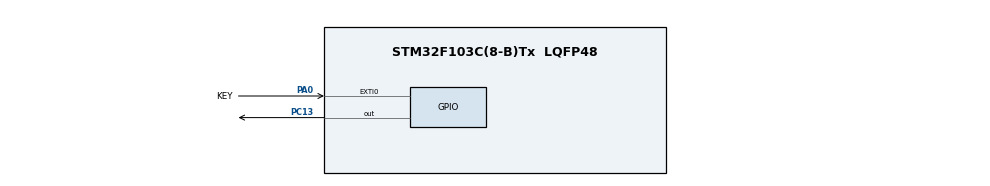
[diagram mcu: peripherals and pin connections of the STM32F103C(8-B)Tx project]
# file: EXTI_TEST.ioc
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Mcu.Family=STM32F1
Mcu.Name=STM32F103C(8-B)Tx
Mcu.Package=LQFP48
NVIC.EXTI0_IRQn=true\:0\:0\:false\:false\:true\:true\:true\:true
NVIC.PriorityGroup=NVIC_PRIORITYGROUP_4
PA0-WKUP.GPIO_Label=KEY
PA0-WKUP.GPIO_ModeDefaultEXTI=GPIO_MODE_IT_FALLING
PA0-WKUP.GPIO_PuPd=GPIO_PULLUP
PA0-WKUP.Signal=GPXTI0
PA13.Mode=Serial_Wire
PA13.Signal=SYS_JTMS-SWDIO
PA14.Mode=Serial_Wire
PA14.Signal=SYS_JTCK-SWCLK
PC13-TAMPER-RTC.GPIO_ModeDefaultOutputPP=GPIO_MODE_OUTPUT_OD
PC13-TAMPER-RTC.GPIO_PuPd=GPIO_NOPULL
PC13-TAMPER-RTC.PinState=GPIO_PIN_SET
PC13-TAMPER-RTC.Signal=GPIO_Output
ProjectManager.HeapSize=0x200
ProjectManager.StackSize=0x400
ProjectManager.TargetToolchain=MDK-ARM V5.32
RCC.APB1Freq_Value=8000000
RCC.APB2Freq_Value=8000000
board=custom

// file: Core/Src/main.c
/* USER CODE BEGIN Header */
/**
  ******************************************************************************
  * @file           : main.c
  * @brief          : Main program body
  ******************************************************************************
  * @attention
  *
  * Copyright (c) 2026 STMicroelectronics.
  * All rights reserved.
  *
  * This software is licensed under terms that can be found in the LICENSE file
  * in the root directory of this software component.
  * If no LICENSE file comes with this software, it is provided AS-IS.
  *
  ******************************************************************************
  */
/**
  * 工程：EXTI_Test —— 外部中断 + 软件消抖 + LED 翻转
  * 硬件：KEY 接 PA0（内部上拉，下降沿触发，按下接 GND）；LED 接 PC13（开漏输出，低电平点亮）
  * 时钟：只用内部 HSI 8 MHz，未启用 HSE，也没有开 PLL
  * 思路：EXTI 回调里只置标志、记时间戳，耗时的判断放到主循环，中断保持最短
  * 验证：每按一次按键，PC13 上的 LED 翻转一次
  */
/* USER CODE END Header */
#include "main.h"
#include "gpio.h"

void SystemClock_Config(void);

/* USER CODE BEGIN 0 */
volatile uint8_t key_flag=0;			// 中断置 1，通知主循环“有按键事件”；volatile 防止编译器把它缓存进寄存器
volatile uint32_t key_press_tick = 0;	// 记下按下时刻的 SysTick 毫秒数，主循环靠它算 20 ms 消抖窗口
/* USER CODE END 0 */

int main(void)
{

  /* MCU Configuration--------------------------------------------------------*/

  /* Reset of all peripherals, Initializes the Flash interface and the Systick. */
  HAL_Init();

  /* Configure the system clock */
  SystemClock_Config();

  /* Initialize all configured peripherals */
  MX_GPIO_Init();

  /* Infinite loop */
  /* USER CODE BEGIN WHILE */
  while (1)
  {
		/* 主循环：检测中断置下的标志，完成消抖确认后再翻转 LED */
		if(key_flag == 1)
		{
			/* 距按下已过 20 ms 才继续。机械抖动一般 <10 ms，等过再判定；
			   用“现在 - 当时”而不是“现在 > 当时+20”，是为了让 SysTick 回绕时依然算得对 */
			if((HAL_GetTick() - key_press_tick) >= 20)
			{
				key_flag = 0;		// 清标志：同一次按下只处理一次
				/* 再读一次引脚电平：仍为低说明是真按下，而不是抖动残留或已经松手 */
				if(HAL_GPIO_ReadPin(GPIOA, GPIO_PIN_0) == GPIO_PIN_RESET)
				{
					HAL_GPIO_TogglePin(GPIOC, GPIO_PIN_13);	// 翻转 LED：PC13 是开漏接上拉，低电平点亮
				}
			}

		}
    /* USER CODE END WHILE */

  }
}

void SystemClock_Config(void)
{
  RCC_OscInitTypeDef RCC_OscInitStruct = {0};
  RCC_ClkInitTypeDef RCC_ClkInitStruct = {0};

  /** Initializes the RCC Oscillators according to the specified parameters
  * in the RCC_OscInitTypeDef structure.
  */
  RCC_OscInitStruct.OscillatorType = RCC_OSCILLATORTYPE_HSI;
  RCC_OscInitStruct.HSIState = RCC_HSI_ON;
  RCC_OscInitStruct.HSICalibrationValue = RCC_HSICALIBRATION_DEFAULT;
  RCC_OscInitStruct.PLL.PLLState = RCC_PLL_NONE;
  if (HAL_RCC_OscConfig(&RCC_OscInitStruct) != HAL_OK)
  {
    Error_Handler();
  }

  /** Initializes the CPU, AHB and APB buses clocks
  */
  RCC_ClkInitStruct.ClockType = RCC_CLOCKTYPE_HCLK|RCC_CLOCKTYPE_SYSCLK
                              |RCC_CLOCKTYPE_PCLK1|RCC_CLOCKTYPE_PCLK2;
  RCC_ClkInitStruct.SYSCLKSource = RCC_SYSCLKSOURCE_HSI;
  RCC_ClkInitStruct.AHBCLKDivider = RCC_SYSCLK_DIV1;
  RCC_ClkInitStruct.APB1CLKDivider = RCC_HCLK_DIV1;
  RCC_ClkInitStruct.APB2CLKDivider = RCC_HCLK_DIV1;

  if (HAL_RCC_ClockConfig(&RCC_ClkInitStruct, FLASH_LATENCY_0) != HAL_OK)
  {
    Error_Handler();
  }
}

/* USER CODE BEGIN 4 */

void HAL_GPIO_EXTI_Callback(uint16_t GPIO_Pin)
{
	/* EXTI 中断回调，运行在中断上下文里：只做最短的事 */
	if(GPIO_Pin == KEY_Pin)			// 只处理 PA0（EXTI0），别的引脚的中断不理会
	{
		key_flag = 1;				// 置标志，真正的判断留给主循环
		key_press_tick = HAL_GetTick();	// 记录按下时刻，作为消抖计时的起点
	}
}

/* USER CODE END 4 */

void Error_Handler(void)
{
  __disable_irq();
  while (1)
  {
  }
}
